# CH32V00xxx register map
Vendor: WCH Ltd.; File version: 1.0
CH32V00xxx View File
Registers are 32-bit, read-write, reset 0x0 unless marked. A register's access mark holds for its fields unless they carry their own. Offsets are from the block's base; lines under a group give offsets from that group; [hi:lo] are bit positions; {n}, {i} and the like mark numbered series; 'fields as' and 'values as' point back to an identical list; <NAME> marks a mode.

## Memory map
0x1FFFF7E0 ESIG size 0x14 — Device electronic signature
0x40000000 TIM2 size 0x400 — General purpose timer
0x40002C00 WWDG size 0x400 — Window watchdog
0x40003000 IWDG size 0x400 — Independent watchdog
0x40005400 I2C1 size 0x400 — Inter integrated circuit
0x40007000 PWR size 0x400 — Power control
0x40010000 AFIO size 0x400 — Alternate function I/O
0x40010400 EXTI size 0x400
0x40010800 GPIOA size 0x400 — General purpose I/O
0x40011000 GPIOC size 0x400
0x40011400 GPIOD size 0x400
0x40012400 ADC1 size 0x400 — Analog to digital converter
0x40012C00 TIM1 size 0x400 — Advanced timer
0x40013000 SPI1 size 0x400 — Serial peripheral interface
0x40013800 USART1 size 0x400 — Universal synchronous asynchronous receiver transmitter
0x40020000 DMA1 size 0x400 — DMA1 controller
0x40021000 RCC size 0x400 — Reset and clock control
0x40022000 FLASH size 0x400
0x40023800 EXTEND size 0x400 — Extend configuration
0xE000D000 DBG size 0x400 — Debug support
0xE000E000 PFIC size 0x1100 — Programmable Fast Interrupt Controller
0xE000F000 SYSTICK — Systick registers, 32-bit downcounter for QingKeV2

## Interrupts
16 WWDG — Window Watchdog interrupt
17 PVD (PWR) — PVD through EXTI line detection interrupt
18 FLASH — Flash global interrupt
19 RCC — RCC global interrupt
20 EXTI7_0 (EXTI) — EXTI Line[7:0] interrupt
21 AWU (PWR) — AWU global interrupt
22 DMA1_Channel1 (DMA1) — DMA1 Channel1 global interrupt
23 DMA1_Channel2 (DMA1) — DMA1 Channel2 global interrupt
24 DMA1_Channel3 (DMA1) — DMA1 Channel3 global interrupt
25 DMA1_Channel4 (DMA1) — DMA1 Channel4 global interrupt
26 DMA1_Channel5 (DMA1) — DMA1 Channel5 global interrupt
27 DMA1_Channel6 (DMA1) — DMA1 Channel6 global interrupt
28 DMA1_Channel7 (DMA1) — DMA1 Channel7 global interrupt
29 ADC (ADC1) — ADC global interrupt
30 I2C1_EV (I2C1) — I2C1 event interrupt
31 I2C1_ER (I2C1) — I2C1 error interrupt
32 USART1 — USART1 global interrupt
33 SPI1 — SPI1 global interrupt
34 TIM1_BRK (TIM1) — TIM1 Break interrupt
35 TIM1_UP (TIM1) — TIM1 Update interrupt
36 TIM1_TRG_COM (TIM1) — TIM1 Trigger and Commutation interrupts
37 TIM1_CC (TIM1) — TIM1 Capture Compare interrupt
38 TIM2 — TIM2 global interrupt

## PWR — Power control
Base 0x40007000
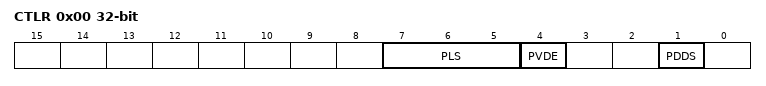
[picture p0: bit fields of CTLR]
0x00 CTLR — Power control register (PWR_CTRL)
  [7:5] PLS — PVD Level Selection
  [4] PVDE — Power Voltage Detector Enable
  [1] PDDS — Power Down Deep Sleep
0x04 CSR ro — Power control state register (PWR_CSR)
  [2] PVDO — PVD Output
0x08 AWUCSR — Automatic wake-up control state register (PWR_AWUCSR)
  [1] AWUEN — Automatic wake-up enable
0x0C AWUAPR reset 0x3F — Automatic wake window comparison value register (PWR_AWUAPR)
  [5:0] AWUAPR — AWU window value
0x10 AWUPSC — Automatic wake-up prescaler register (PWR_AWUPSC)
  [3:0] AWUPSC — Wake-up prescaler

## RCC — Reset and clock control
Base 0x40021000
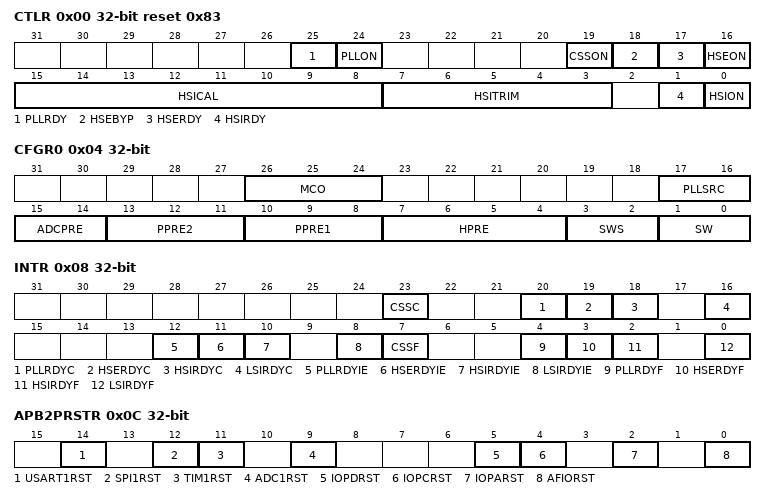
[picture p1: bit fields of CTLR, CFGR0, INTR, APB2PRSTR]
0x00 CTLR access per field reset 0x83 — Clock control register
  [25] PLLRDY ro — PLL clock ready flag
  [24] PLLON rw — PLL enable
  [19] CSSON rw — Clock Security System enable
  [18] HSEBYP rw — External High Speed clock Bypass
  [17] HSERDY ro — External High Speed clock ready flag
  [16] HSEON rw — External High Speed clock enable
  [15:8] HSICAL ro — Internal High Speed clock Calibration
  [7:3] HSITRIM rw — Internal High Speed clock trimming
  [1] HSIRDY ro — Internal High Speed clock ready flag
  [0] HSION rw — Internal High Speed clock enable
0x04 CFGR0 access not given — Clock configuration register (RCC_CFGR0)
  [26:24] MCO rw — Microcontroller clock output
  [17:16] PLLSRC — PLL entry clock source
    0=HSI_MUL2 (HSI clock divided by 2 selected as PLL input clock); 3=HSE_MUL2 (HSE clock divided by 2 selected as PLL input clock)
  [15:14] ADCPRE rw — ADC prescaler
  [13:11] PPRE2 rw — APB High speed prescaler (APB2)
  [10:8] PPRE1 rw — APB Low speed prescaler (APB1)
  [7:4] HPRE rw — AHB prescaler
  [3:2] SWS ro — System Clock Switch Status
  [1:0] SW rw — System clock Switch
0x08 INTR access per field — Clock interrupt register (RCC_INTR)
  [23] CSSC wo — Clock security system interrupt clear
  [20] PLLRDYC wo — PLL Ready Interrupt Clear
  [19] HSERDYC wo — HSE Ready Interrupt Clear
  [18] HSIRDYC wo — HSI Ready Interrupt Clear
  [16] LSIRDYC wo — LSI Ready Interrupt Clear
  [12] PLLRDYIE rw — PLL Ready Interrupt Enable
  [11] HSERDYIE rw — HSE Ready Interrupt Enable
  [10] HSIRDYIE rw — HSI Ready Interrupt Enable
  [8] LSIRDYIE rw — LSI Ready Interrupt Enable
  [7] CSSF ro — Clock Security System Interrupt flag
  [4] PLLRDYF ro — PLL Ready Interrupt flag
  [3] HSERDYF ro — HSE Ready Interrupt flag
  [2] HSIRDYF ro — HSI Ready Interrupt flag
  [0] LSIRDYF ro — LSI Ready Interrupt flag
0x0C APB2PRSTR — APB2 peripheral reset register (RCC_APB2PRSTR)
  [14] USART1RST — USART1 reset
  [12] SPI1RST — SPI 1 reset
  [11] TIM1RST — TIM1 timer reset
  [9] ADC1RST — ADC 1 interface reset
  [5] IOPDRST — IO port D reset
  [4] IOPCRST — IO port C reset
  [2] IOPARST — IO port A reset
  [0] AFIORST — Alternate function I/O reset
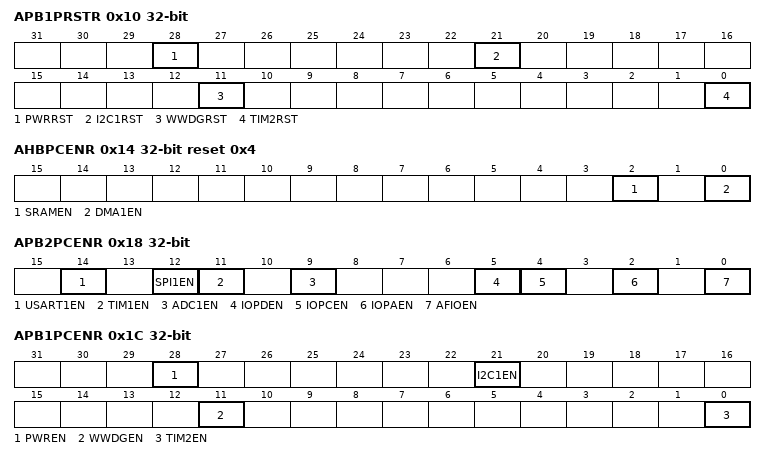
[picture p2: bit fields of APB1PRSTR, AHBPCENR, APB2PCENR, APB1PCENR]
0x10 APB1PRSTR — APB1 peripheral reset register (RCC_APB1PRSTR)
  [28] PWRRST — Power interface reset
  [21] I2C1RST — I2C1 reset
  [11] WWDGRST — Window watchdog reset
  [0] TIM2RST — TIM2 reset
0x14 AHBPCENR reset 0x4 — AHB Peripheral Clock enable register (RCC_AHBPCENR)
  [2] SRAMEN — SRAM interface clock enable
  [0] DMA1EN — DMA clock enable
0x18 APB2PCENR — APB2 peripheral clock enable register (RCC_APB2PCENR)
  [14] USART1EN — USART1 clock enable
  [12] SPI1EN — SPI 1 clock enable
  [11] TIM1EN — TIM1 Timer clock enable
  [9] ADC1EN — ADC1 interface clock enable
  [5] IOPDEN — I/O port D clock enable
  [4] IOPCEN — I/O port C clock enable
  [2] IOPAEN — I/O port A clock enable
  [0] AFIOEN — Alternate function I/O clock enable
0x1C APB1PCENR — APB1 peripheral clock enable register (RCC_APB1PCENR)
  [28] PWREN — Power interface clock enable
  [21] I2C1EN — I2C 1 clock enable
  [11] WWDGEN — Window watchdog clock enable
  [0] TIM2EN — Timer 2 clock enable
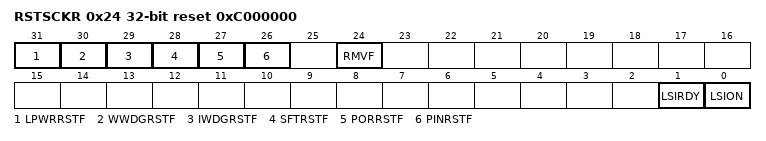
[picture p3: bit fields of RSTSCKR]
0x24 RSTSCKR access per field reset 0xC000000 — Control/status register (RCC_RSTSCKR)
  [31] LPWRRSTF ro — Low-power reset flag
  [30] WWDGRSTF ro — Window watchdog reset flag
  [29] IWDGRSTF ro — Independent watchdog reset flag
  [28] SFTRSTF ro — Software reset flag
  [27] PORRSTF ro — POR/PDR reset flag
  [26] PINRSTF ro — PIN reset flag
  [24] RMVF rw — Remove reset flag
  [1] LSIRDY ro — Internal low speed oscillator ready
  [0] LSION rw — Internal low speed oscillator enable
